VERSION ""

NS_ :

BS_:

BU_: Sensor_Board Steering_Wheel_Sensor Accelerometer Dashboard Wireless_Board Shutdown_Circuit BMS MCU Diagnostics Motor_Control VCU
VAL_TABLE_ MCU_Config_Parameter 14 "Undervoltage Min Voltage" 13 "Undervoltage Limit Gain" 12 "Undervoltage Limit" 11 "Overvoltage Limit" 10 "Motor Phase Offset Compensation" 9 "Auto-Aligning Current" 8 "Feedback Resolution" 7 "Feedback Type" 6 "Motor Temperature Sensor" 5 "Motor Rated Torque" 4 "Motor Rated Current" 3 "Motor Pole Pairs" 2 "FOC Delay" 1 "Motor type" 0 "Start up" ;
VAL_TABLE_ MCU_NMT_Mode 3 "Operational" 2 "Pre-Operational" 1 "Reset" 0 "Stopped" ;
VAL_TABLE_ Pedal_Sensor_Failure_Mode 4 "Complete pedal box failure" 3 "Brake sensor failure" 2 "Throttle sensor 2 failure" 1 "Throttle sensor 1 failure" 0 "No error, pedal sensors ok" ;
VAL_TABLE_ MCU_Error_Codes 5 "Description for the value '0x5'" 4 "Description for the value '0x4'" 3 "Description for the value '0x3'" 2 "Description for the value '0x2'" 1 "Description for the value '0x1'" 0 "Description for the value '0x0'" ;
VAL_TABLE_ Statusword_values 13 "Fault_Off" 8 "Enabled" 7 "Energised" 4 "Precharge" 2 "Shutdown" 1 "Not_ready_to_switch_on" 0 "None" ;
VAL_TABLE_ Heartbeat 127 "System in pre-operational mode" 5 "System in operational mode" 0 "boot-up" ;
VAL_TABLE_ OperationValues 128 "Return to pre-operational" 1 "Enable operational" ;
VAL_TABLE_ Fault_Codes 18575 "Sensorless Startup" 17868 "Mains Over Voltage" 19585 "HVIL loop Broken" 22401 "CANopen Anon EMCY level 5" 22337 "Invalid power Frame rating" 21711 "IGBT M3 High driver" 21710 "IGBT M3 Low driver" 21709 "IGBT M2 High driver" 21708 "IGBT M2 Low driver" 21707 "IGBT M1 High driver" 21706 "Pump FET s/c, IGBT M1 Low driver" 21705 "MOSFET short circuit checks" 21704 "MOSFET s/c M3 to B-" 21703 "MOSFET s/c M3 to B+" 21702 "MOSFET s/c M2 to B-" 21701 "MOSFET s/c M2 to B+" 21700 "MOSFET s/c M1 to B-" 21699 "MOSFET s/c M1 to B+" 21698 "Power Frame Fault" 21697 "PF Overvoltage" 21570 "Calibration Fault" 21569 "Incompatible hardware version" 21377 "CANopen EMCY level 4" 21318 "Internal Supply Out of Range" 21317 "Sheduler Stack Overflow" 21316 "DSP SPI comms Fault" 21315 "Fault List Overflow" 21314 "OSC watchdog Fault" 21313 "Invalid DSP protocol" 21274 "Ren Protocol" 21273 "Mtr Slave in wrong state" 21272 "SDO Bad Error Number" 21271 "SDO Bad SRC" 21270 "SDO Unknown" 21269 "SDO Send Error" 21268 "SDO Len Error" 21267 "SDO Rec Error" 21266 "SDO Toggle Error" 21265 "SDO State Error" 21264 "SDO Abort Error" 21263 "SDO Timeout Error" 21262 "SDO HDL Error" 21261 "CAN ESTAT set" 21260 "CANopen salve in wrong state" 21259 "CANopen Heartbeat Failed" 21258 "Short PDO Recieved" 21257 "Node guarding Failed" 21256 "CAN Off bus" 21255 "CAN overrun" 21254 "HPTX queue overrun" 21253 "HPRX queue overrun" 21252 "LPTX queue overrun" 21251 "LPRX queue overrun" 21250 "Bootup not recieved" 21249 "CANbus Fault" 21191 "Vcap Over Voltage" 21190 "di/dt Fault" 21189 "Encoder Alignment Severe" 21188 "Motor Overspeed Fault" 21187 "Current Control Fault" 21186 "Motor Over Current" 21185 "Encoder Fault" 20993 "Heatsink Overtemp" 20931 "KL 15/30 too High" 20930 "Capacitor Precharge Failure" 20929 "Power Supply Interrupt" 20872 "AOut short Circuit" 20871 "AOut Under Current" 20870 "AOut Over Temperature" 20869 "AOut Off with FS" 20868 "AOut on without FS" 20867 "Analogue Output Over Current" 20866 "Analogue Input Wire Off" 20865 "Digital Input Wire Off" 20803 "VERLOG" 20802 "Ren Signal" 20801 "BeltLoader Fault" 20738 "Line Contactro Welded" 20737 "Line Contactor O/C" 20609 "Invalid Steer Switches" 20550 "Voltage Auto Config Error" 20549 "Auto Configuration Fault" 20548 "Dynamic Range Error" 20547 "Static Range Error" 20546 "VPDO out of range" 20545 "BAD NVM data" 20353 "CANopen Anon EMCY level 3" 20311 "Motor Stalled" 20310 "Motor in Wrong Direction" 20309 "DSP Parameter Error" 20308 "AutoZero Range Error" 20307 "App Manager SS " 20306 "DSP Comms Error" 20305 "DSP Not Detected" 20304 "New Power Frame Detected" 20303 "Trac APP SS Error" 20302 "DMC SS Error" 20301 "VA SS Error" 20300 "OBD SS Error" 20299 "LCP SS Error" 20298 "LCM SS Error" 20297 "GIO SS Error" 20296 "I/O SS Error" 20295 "DSP Heartbeat Error" 20294 "Sheduler Error" 20293 "Queue Error" 20292 "Timer Failed" 20291 "General DSP Error" 20290 "Out Of Memory" 20289 "Internal Fault" 20226 "EMCY send Failed" 20225 "Unexpected Slave State" 20162 "Pulsing Disabled" 20161 "Can't Establush field current" 20097 "RPDO Timeout (severe)" 19907 "Power Supply Critical" 19779 "Motor Stalled" 19778 "Motor Open Circuit Fault" 19777 "Motor Isolation Fault" 19716 "Circuit Breaker Timeout" 19715 "DC Link Collapsed" 19714 "Circuit Breaker Welded" 19713 "Circuit Breaker Open" 19521 "Too Many Slaves" 19329 "CANopen EMCY level 2" 19203 "IO Data Error" 19202 "Ren Data" 19201 "CANbus Off (drive inhibit)" 19073 "RPDO Timeout (drive inhibit)" 18945 "Cutback" 18882 "Entering Cutback" 18819 "Direction Change" 18818 "E-Brake Wire Off" 18817 "Throttle Fault" 18754 "PST Fault" 18753 "Motor Overspeed" 18574 "Mom Dir Fault" 18573 "Belly Fault" 18572 "Tilt Sensor Fault" 18571 "Illegal Mode Fault" 18570 "Traction inhibit Fault" 18569 "Pothole Fault" 18568 "Raised and Tilted Fault" 18567 "Overload Fault" 18566 "Inch Fault" 18565 "FS1 Recycle Fault" 18564 "Sequence Fault" 18563 "SRO Fault" 18562 "Two Direction Fault" 18561 "Seat Fault" 18369 "Vehicle Service required" 18307 "24V Supply High" 18306 "24V Supplu Low" 18305 "CANopen Anon EMCY level 1" 18242 "Internal Supply Out of range" 18241 "Sheduler Stack Overflow warning" 18177 "CAN Warning" 18118 "Encoder PLL Deactivated Warning" 18117 "Stator Resistance Error" 18116 "Motor Pull-Out Warning" 18115 "Fault Ride through" 18114 "SinCos Tracking warning" 18113 "Encoder Alignment warning" 18051 "RPDO Timeout (warning)" 18050 "Io can't init" 18049 "Unit in Pre-Op" 17924 "Motor too Cold" 17923 "Motor in Thermal Cutback" 17922 "Device too hot" 17921 "Device too cold" 17870 "Vcap Vkey Diff" 17869 "KL15/30 too low" 17867 "Mains Under voltage" 17866 "Motor in high voltage cutback" 17865 "Motor in low voltage cutback" 17864 "Vcap Above rated max" 17863 "Vbat Above rated max" 17862 "Vbat Below rated min" 17861 "High Capacitor Cut" 17860 "High Battery Cut" 17859 "Low Battery Cut" 17858 "BDI Cutout" 17857 "BDI warning" 17802 "Seat warning" 17801 "Analogue Supply warning" 17800 "AOut Short Circuit (warn)" 17799 "AOut Under Current (warn)" 17798 "AOut Over Temperature (warn)" 17797 "AOut Off with Failsafe [warn]" 17796 "AOut Over Current [warn]" 17795 "Safety Case 2" 17794 "Safety Case 1" 17793 "Throttle Fault (Warn)" 17741 "Electrolyte Cutout Level" 17740 "Electrolyte Level Low" 17739 "MOSFET s/c test Waiting" 17738 "Bridge Enable Delayed" 17737 "Pulsed Enable" 17736 "Steer Sensor Warning" 17735 "Tow Mode" 17734 "No Motor Speed Signal" 17733 "Isolation Fault" 17732 "Pump Current Low" 17731 "Hydraulic Fault" 17730 "Low Oil / Device test waiting" 17729 "Fan Fault" 17537 "Handbrake Fault" ;

BO_ 3221225472 VECTOR__INDEPENDENT_SIG_MSG: 0 Vector__XXX
 SG_ Test_Sig : 0|8@1- (1,0) [0|0] "" Vector__XXX
 SG_ BrakePot_Voltage : 0|16@1+ (1,0) [0|65535] "mV" Vector__XXX
 SG_ GPS_Long : 0|16@1+ (1,0) [0|65535] "" Vector__XXX
 SG_ MCU_Error : 0|1@1+ (1,0) [0|1] "" Vector__XXX
 SG_ Motor_Temp : 0|8@1+ (1,0) [0|255] "Celsius" Vector__XXX
 SG_ MCU_Command : 0|1@1+ (1,0) [0|1] "" Vector__XXX
 SG_ GPS_Lat : 0|16@1+ (1,0) [0|65535] "" Vector__XXX
 SG_ MCU_On : 0|1@1+ (1,0) [0|1] "" Vector__XXX
 SG_ MCU_Pre_Op : 0|1@1+ (1,0) [0|1] "" Vector__XXX
 SG_ MCU_Op : 0|1@1+ (1,0) [0|1] "" Vector__XXX
 SG_ MCU_Supply_Voltage : 0|16@1+ (1,0) [0|65535] "V" Vector__XXX
 SG_ MCU_Target_Velocity : 0|32@1+ (1,0) [0|4294967295] "V" Vector__XXX
 SG_ MCU_DC_Power : 0|32@1- (1,0) [0|0] "W" Vector__XXX
 SG_ MCU_Error_Code : 0|16@1- (1,0) [0|0] "" Vector__XXX
 SG_ MCU_Status_Word : 0|16@1+ (1,0) [0|65535] "" Vector__XXX
 SG_ MCU_DC_Link_Current : 0|32@1- (1,0) [-2147483648|2147483647] "A" Vector__XXX
 SG_ MCU_DC_Link_Voltage : 0|16@1- (0.1,0) [-32768|32767] "V" Vector__XXX
 SG_ MCU_Temp : 0|8@1+ (1,0) [0|255] "Celsius" Vector__XXX
 SG_ MCU_Torque_Actual_Value : 0|16@1- (1,0) [-32768|32767] "" Vector__XXX
 SG_ MCU_Warning : 0|1@1+ (1,0) [0|1] "" Vector__XXX
 SG_ MCU_Config_Error : 0|1@1+ (1,0) [0|1] "" Vector__XXX
 SG_ Heartbeat : 0|8@1- (1,0) [0|0] "" Vector__XXX
 SG_ SDO_Specifier : 0|8@1+ (1,0) [0|0] "" Vector__XXX
 SG_ MCU_OD_Sub_Index : 0|8@1+ (1,0) [0|255] "" Vector__XXX
 SG_ MCU_OD_Index : 0|16@1+ (1,0) [0|65535] "" Vector__XXX
 SG_ SDO_Data : 0|32@1- (1,0) [0|4294967295] "" Vector__XXX
 SG_ SDO_Data : 0|32@1- (1,0) [0|4294967295] "" Vector__XXX
 SG_ MCU_OD_Sub_Index : 0|8@1+ (1,0) [0|255] "" Vector__XXX
 SG_ MCU_OD_Index : 0|16@1+ (1,0) [0|65535] "" Vector__XXX
 SG_ SDO_Specifier : 0|8@1+ (1,0) [0|255] "" Vector__XXX
 SG_ RegenSpeedSig : 0|16@1- (1,0) [0|0] "" Vector__XXX
 SG_ MCU_Torque_Request : 0|16@1- (1,0) [-1000|1000] "" Vector__XXX
 SG_ MCU_ControlWord : 0|16@1+ (1,0) [0|65535] "" Vector__XXX
 SG_ NMT_Command_0 : 0|8@1+ (1,0) [0|0] "" Vector__XXX
 SG_ Vehicle_Speed : 0|16@1+ (0.01,0) [0|655.35] "" Vector__XXX
 SG_ Rear_Wheel_Speed : 0|16@1+ (0.01,0) [0|655.35] "km/h" Vector__XXX
 SG_ Front_Left_Wheel_Interval : 0|32@1+ (1,0) [0|4294967295] "uS" Vector__XXX
 SG_ Front_Right_Wheel_Interval : 0|32@1+ (1,0) [0|4294967295] "uS" Vector__XXX
 SG_ Rear_Left_Wheel_Interval : 0|32@1+ (1,0) [0|4294967295] "uS" Vector__XXX
 SG_ Rear_Right_Wheel_Interval : 0|32@1+ (1,0) [0|4294967295] "uS" Vector__XXX

BO_ 1284 Wheel_Speed_4: 8 Vector__XXX

BO_ 1283 Wheel_Speed_3: 8 Vector__XXX

BO_ 392 MCU_TPDO5: 0 MCU

BO_ 2019 DashBMSReq: 8 Dashboard

BO_ 564 SteeringWheelSensor: 5 Steering_Wheel_Sensor
 SG_ RotationSpeed : 16|8@1+ (4,0) [0|0] "" Vector__XXX
 SG_ Acc_Angle : 0|16@1- (0.1,0) [0|0] "Degrees" Vector__XXX

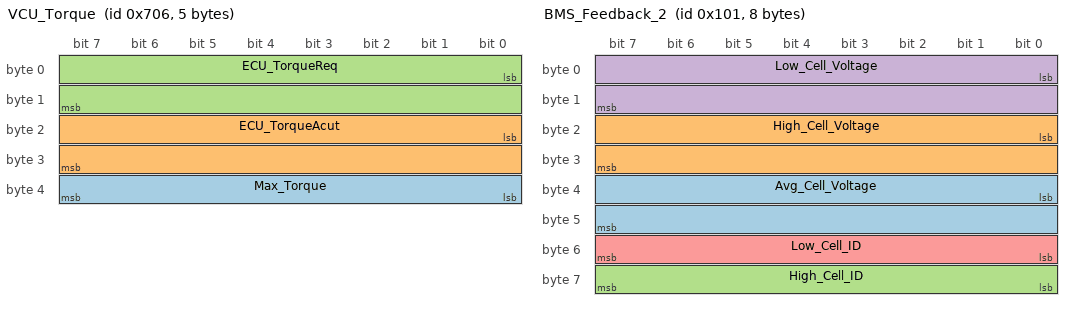
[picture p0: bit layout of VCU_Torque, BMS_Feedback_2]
BO_ 1798 VCU_Torque: 5 VCU
 SG_ Max_Torque : 32|8@1- (1,0) [0|0] "" Vector__XXX
 SG_ ECU_TorqueAcut : 16|16@1- (0.1,0) [0|0] "Percent" Vector__XXX
 SG_ ECU_TorqueReq : 0|16@1- (0.1,0) [0|0] "Percent" Vector__XXX

BO_ 380 AccelerometerZ: 8 Accelerometer
 SG_ Acc_ZAxis : 32|16@1+ (0.0001274,0) [0|0] "" Vector__XXX

BO_ 376 AccelerometerX: 8 Accelerometer
 SG_ Acc_XAxis : 32|16@1+ (0.0001274,0) [0|0] "" Vector__XXX
 SG_ Acc_Roll : 0|16@1+ (0.005,0) [0|0] "" Vector__XXX

BO_ 372 AccelerometerY: 8 Accelerometer
 SG_ Acc_YAxis : 32|16@1+ (0.0001274,0) [0|0] "" Vector__XXX
 SG_ Acc_Yaw : 0|16@1+ (0.005,0) [0|0] "" Vector__XXX

BO_ 1282 Wheel_Speeds_2: 6 Sensor_Board

BO_ 1281 Wheel_Speed_1: 6 Wireless_Board

BO_ 769 MCU_RPDO2: 8 VCU

BO_ 513 MCU_RPDO1: 0 VCU

BO_ 1077 MCU_TPDO4: 0 MCU

BO_ 338 MCU_TPDO3: 0 MCU

BO_ 569 MCU_TPDO2: 0 MCU

BO_ 272 MCU_TPDO1: 0 MCU

BO_ 257 BMS_Feedback_2: 8 BMS
 SG_ Avg_Cell_Voltage : 32|16@1+ (0.1,0) [0|6553.5] "mV" Vector__XXX
 SG_ High_Cell_Voltage : 16|16@1+ (0.1,0) [0|6553.5] "mV" Vector__XXX
 SG_ High_Cell_ID : 56|8@1+ (1,0) [0|255] "" Vector__XXX
 SG_ Low_Cell_Voltage : 0|16@1+ (0.1,0) [0|6553.5] "mV" Vector__XXX
 SG_ Low_Cell_ID : 48|8@1+ (1,0) [0|255] "" Vector__XXX

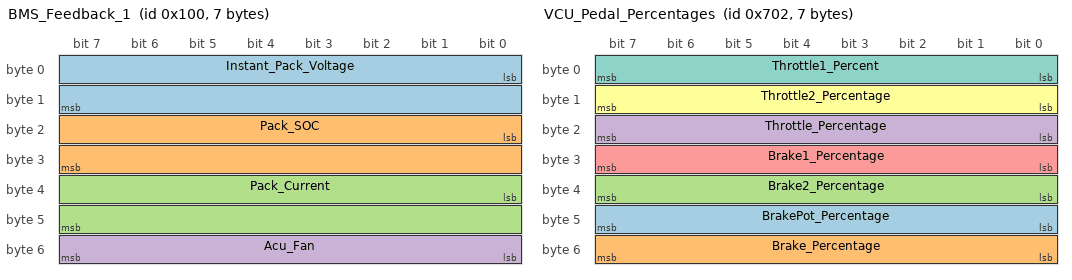
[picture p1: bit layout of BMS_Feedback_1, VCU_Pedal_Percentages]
BO_ 256 BMS_Feedback_1: 7 BMS
 SG_ Instant_Pack_Voltage : 0|16@1+ (1,0) [0|65535] "" Vector__XXX
 SG_ Pack_SOC : 16|16@1+ (1,0) [0|65535] "" Vector__XXX
 SG_ Pack_Current : 32|16@1- (1,64) [0|65535] "" Vector__XXX
 SG_ Acu_Fan : 48|8@1+ (1,0) [0|255] "" Vector__XXX

BO_ 1792 VCU_Diagnostics: 8 VCU
 SG_ VCU_Year : 48|8@1+ (1,0) [0|255] "" Vector__XXX
 SG_ VCU_Version : 56|8@1+ (1,0) [0|255] "" Vector__XXX
 SG_ VCU_Month : 40|8@1+ (1,0) [0|255] "" Vector__XXX
 SG_ VCU_Day : 35|5@1+ (1,0) [0|31] "" Vector__XXX
 SG_ Boost_on : 34|1@1- (1,0) [0|0] "" Vector__XXX
 SG_ TC_on : 33|1@1- (1,0) [0|0] "" Vector__XXX
 SG_ RegenBool : 32|1@1- (1,0) [0|0] "" Vector__XXX
 SG_ Fault_ECU_Shutdown : 22|1@1- (1,0) [0|0] "" Vector__XXX
 SG_ Low_AIR_Status : 20|1@1- (1,0) [0|0] "" Vector__XXX
 SG_ High_AIR_Status : 21|1@1+ (1,0) [0|1] "" Vector__XXX
 SG_ BPPS_Implausibility : 16|1@1- (1,0) [0|0] "" Vector__XXX
 SG_ Pedal_Sensor_Fail : 24|8@1+ (1,0) [0|7] "" Vector__XXX
 SG_ APPS_Implausibility : 17|1@1+ (1,0) [0|1] "" Vector__XXX
 SG_ APPS_BP_Implausibility : 18|1@1+ (1,0) [0|1] "" Vector__XXX
 SG_ GearingRatio : 8|8@1+ (0.1,0) [0|0] "" Vector__XXX
 SG_ Wheel_Size : 0|8@1+ (0.1,0) [0|25.5] "m" Vector__XXX
 SG_ Fault_CarShutdown : 23|1@1+ (1,0) [0|1] "" Vector__XXX
 SG_ LV_Battery_Warning : 19|1@1+ (1,0) [0|1] "" Vector__XXX

BO_ 1794 VCU_Pedal_Percentages: 7 VCU
 SG_ BrakePot_Percentage : 40|8@1+ (1,0) [0|255] "%" Vector__XXX
 SG_ Brake_Percentage : 48|8@1+ (1,0) [0|255] "%" Vector__XXX
 SG_ Brake2_Percentage : 32|8@1+ (1,0) [0|255] "%" Vector__XXX
 SG_ Throttle_Percentage : 16|8@1+ (1,0) [0|255] "%" Vector__XXX
 SG_ Brake1_Percentage : 24|8@1+ (1,0) [0|255] "%" Vector__XXX
 SG_ Throttle2_Percentage : 8|8@1+ (1,0) [0|255] "%" Vector__XXX
 SG_ Throttle1_Percent : 0|8@1+ (1,0) [0|255] "%" Vector__XXX

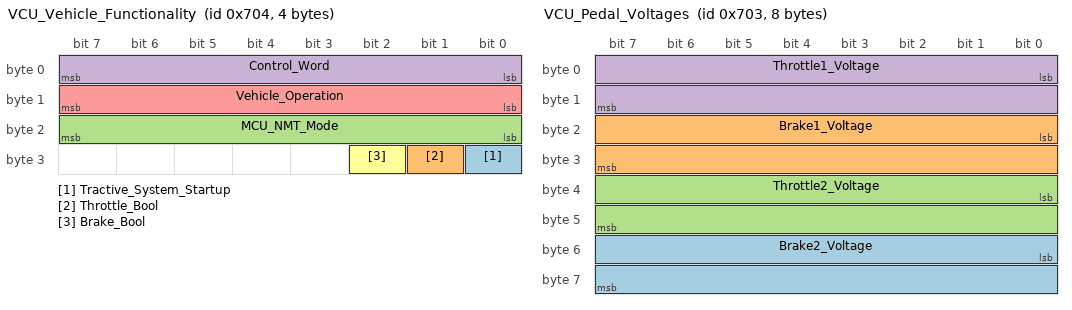
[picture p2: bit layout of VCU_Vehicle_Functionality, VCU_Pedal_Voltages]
BO_ 1796 VCU_Vehicle_Functionality: 4 VCU
 SG_ Tractive_System_Startup : 24|1@1+ (1,0) [0|255] "" Vector__XXX
 SG_ Throttle_Bool : 25|1@1+ (1,0) [0|1] "" Vector__XXX
 SG_ MCU_NMT_Mode : 16|8@1+ (1,0) [0|255] "" Vector__XXX
 SG_ Control_Word : 0|8@1+ (1,0) [0|1] "" Vector__XXX
 SG_ Vehicle_Operation : 8|8@1+ (1,0) [0|15] "" Vector__XXX
 SG_ Brake_Bool : 26|1@1+ (1,0) [0|1] "" Vector__XXX

BO_ 1795 VCU_Pedal_Voltages: 8 VCU
 SG_ Brake2_Voltage : 48|16@1+ (1,0) [0|65535] "mV" Vector__XXX
 SG_ Brake1_Voltage : 16|16@1+ (1,0) [0|65535] "mV" Vector__XXX
 SG_ Throttle2_Voltage : 32|16@1+ (1,0) [0|65535] "mV" Vector__XXX
 SG_ Throttle1_Voltage : 0|16@1+ (1,0) [0|65535] "mV" Vector__XXX

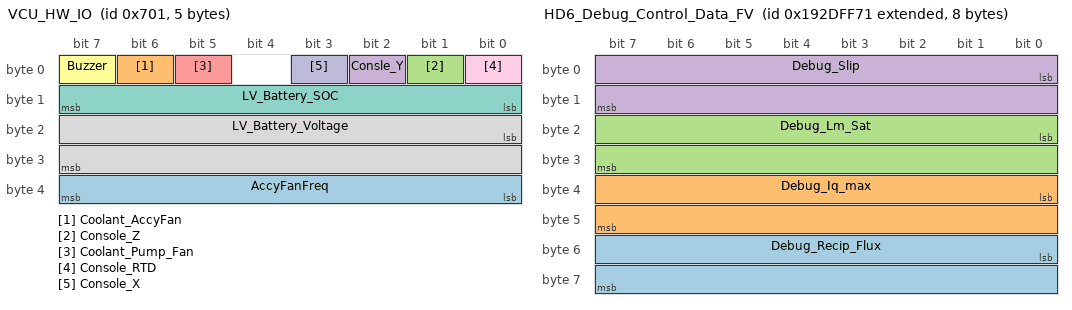
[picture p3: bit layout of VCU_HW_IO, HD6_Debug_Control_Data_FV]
BO_ 1793 VCU_HW_IO: 5 VCU
 SG_ AccyFanFreq : 32|8@1+ (1,0) [0|0] "Hz" Vector__XXX
 SG_ Coolant_AccyFan : 6|1@1- (1,0) [0|0] "" Vector__XXX
 SG_ Console_Z : 1|1@1- (1,0) [0|0] "" Vector__XXX
 SG_ Consle_Y : 2|1@1- (1,0) [0|0] "Bool" Vector__XXX
 SG_ Coolant_Pump_Fan : 5|1@1+ (1,0) [0|1] "" Vector__XXX
 SG_ Buzzer : 7|1@1+ (1,0) [0|1] "" Vector__XXX
 SG_ LV_Battery_SOC : 8|8@1+ (1,0) [0|255] "" Vector__XXX
 SG_ LV_Battery_Voltage : 16|16@1+ (1,0) [0|65535] "mV" Vector__XXX
 SG_ Console_RTD : 0|1@1+ (1,0) [0|1] "Bool" Vector__XXX
 SG_ Console_X : 3|1@1+ (1,0) [0|1] "Bool" Vector__XXX

BO_ 112 MCU_NMT_Broadcast: 1 VCU
 SG_ NMT_Command : 0|8@1+ (1,0) [0|255] "" Vector__XXX

BO_ 128 MCU_Sync_MSG: 0 VCU

BO_ 2568814449 HS5_Encoder_Info: 8 Motor_Control
 SG_ Encoder_pos : 0|32@1- (1.52587890625E-005,0) [0|0] "rotations" Vector__XXX

BO_ 2569928561 HD6_Debug_Control_Data_FV: 8 Motor_Control
 SG_ Debug_Recip_Flux : 48|16@1- (1,0) [0|0] "1/A" Vector__XXX
 SG_ Debug_Iq_max : 32|16@1- (1,0) [0|0] "A" Vector__XXX
 SG_ Debug_Lm_Sat : 16|16@1- (1.52587890625E-005,0) [0|0] "H" Vector__XXX
 SG_ Debug_Slip : 0|16@1- (0.0625,0) [0|0] "rad/s" Vector__XXX

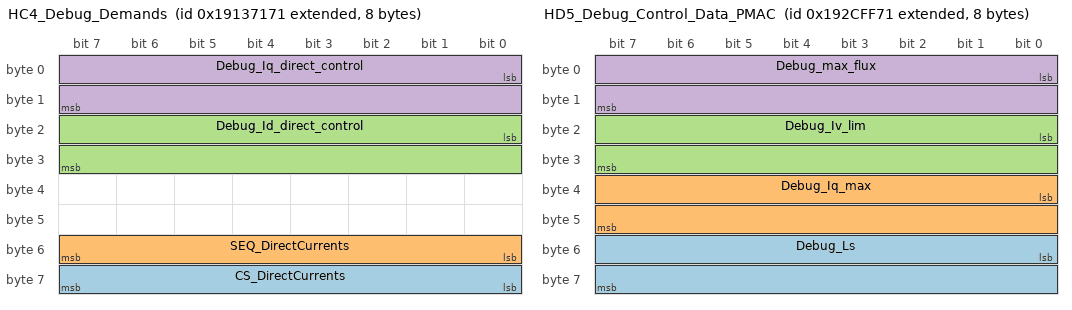
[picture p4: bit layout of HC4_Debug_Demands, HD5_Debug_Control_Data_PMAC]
BO_ 2568188273 HC4_Debug_Demands: 8 Motor_Control
 SG_ CS_DirectCurrents : 56|8@1+ (1,0) [0|0] "" Vector__XXX
 SG_ SEQ_DirectCurrents : 48|8@1+ (1,0) [0|0] "" Vector__XXX
 SG_ Debug_Id_direct_control : 16|16@1- (0.0625,0) [0|0] "A" Vector__XXX
 SG_ Debug_Iq_direct_control : 0|16@1- (0.0625,0) [0|0] "A" Vector__XXX

BO_ 2569863025 HD5_Debug_Control_Data_PMAC: 8 Motor_Control
 SG_ Debug_Ls : 48|16@1- (5.960464477539E-008,0) [0|0] "H" Vector__XXX
 SG_ Debug_Iq_max : 32|16@1- (1,0) [0|0] "A" Vector__XXX
 SG_ Debug_Iv_lim : 16|16@1- (1,0) [0|0] "A" Vector__XXX
 SG_ Debug_max_flux : 0|16@1- (1,0) [0|0] "A" Vector__XXX

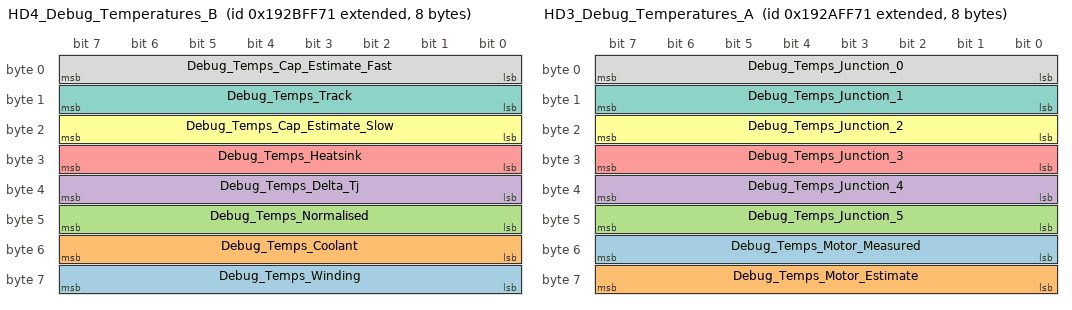
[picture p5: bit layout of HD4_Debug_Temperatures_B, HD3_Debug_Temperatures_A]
BO_ 2569797489 HD4_Debug_Temperatures_B: 8 Motor_Control
 SG_ Debug_Temps_Winding : 56|8@1+ (1,0) [0|0] "degC" Vector__XXX
 SG_ Debug_Temps_Coolant : 48|8@1+ (1,0) [0|0] "degC" Vector__XXX
 SG_ Debug_Temps_Normalised : 40|8@1+ (1,0) [0|255] "degC" Vector__XXX
 SG_ Debug_Temps_Delta_Tj : 32|8@1+ (1,0) [0|255] "degC" Vector__XXX
 SG_ Debug_Temps_Heatsink : 24|8@1+ (1,0) [0|255] "degC" Vector__XXX
 SG_ Debug_Temps_Cap_Estimate_Slow : 16|8@1+ (1,0) [0|255] "degC" Vector__XXX
 SG_ Debug_Temps_Track : 8|8@1+ (1,0) [0|255] "degC" Vector__XXX
 SG_ Debug_Temps_Cap_Estimate_Fast : 0|8@1+ (1,0) [0|255] "degC" Vector__XXX

BO_ 2569731953 HD3_Debug_Temperatures_A: 8 Motor_Control
 SG_ Debug_Temps_Motor_Measured : 48|8@1+ (1,0) [0|255] "degC" Vector__XXX
 SG_ Debug_Temps_Motor_Estimate : 56|8@1+ (1,0) [0|255] "degC" Vector__XXX
 SG_ Debug_Temps_Junction_5 : 40|8@1+ (1,0) [0|255] "degC" Vector__XXX
 SG_ Debug_Temps_Junction_4 : 32|8@1+ (1,0) [0|255] "degC" Vector__XXX
 SG_ Debug_Temps_Junction_3 : 24|8@1+ (1,0) [0|255] "degC" Vector__XXX
 SG_ Debug_Temps_Junction_2 : 16|8@1+ (1,0) [0|255] "degC" Vector__XXX
 SG_ Debug_Temps_Junction_1 : 8|8@1+ (1,0) [0|255] "degC" Vector__XXX
 SG_ Debug_Temps_Junction_0 : 0|8@1+ (1,0) [0|255] "degC" Vector__XXX

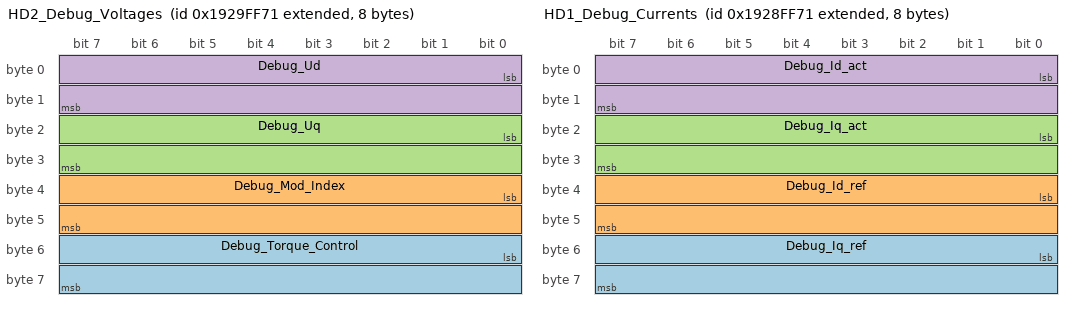
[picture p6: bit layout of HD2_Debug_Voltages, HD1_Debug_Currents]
BO_ 2569666417 HD2_Debug_Voltages: 8 Motor_Control
 SG_ Debug_Torque_Control : 48|16@1- (0.0625,0) [0|0] "Nm" Vector__XXX
 SG_ Debug_Mod_Index : 32|16@1+ (0.00390625,0) [0|0] "%" Vector__XXX
 SG_ Debug_Uq : 16|16@1- (0.0625,0) [0|0] "V" Vector__XXX
 SG_ Debug_Ud : 0|16@1- (0.0625,0) [0|0] "V" Vector__XXX

BO_ 2569600881 HD1_Debug_Currents: 8 Motor_Control
 SG_ Debug_Iq_ref : 48|16@1- (0.0625,0) [0|0] "A" Vector__XXX
 SG_ Debug_Id_ref : 32|16@1- (0.0625,0) [0|0] "A" Vector__XXX
 SG_ Debug_Iq_act : 16|16@1- (0.0625,0) [0|0] "A" Vector__XXX
 SG_ Debug_Id_act : 0|16@1- (0.0625,0) [0|0] "A" Vector__XXX

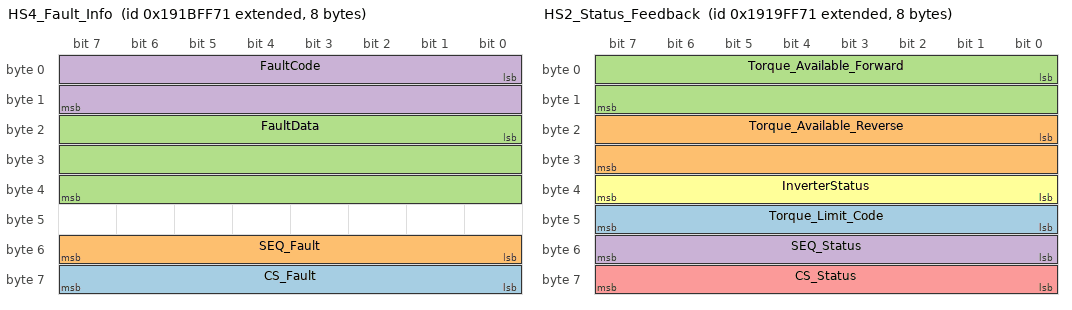
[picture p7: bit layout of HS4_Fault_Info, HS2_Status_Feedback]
BO_ 2568748913 HS4_Fault_Info: 8 Motor_Control
 SG_ CS_Fault : 56|8@1+ (1,0) [0|255] ""  VCU
 SG_ SEQ_Fault : 48|8@1+ (1,0) [0|255] ""  VCU
 SG_ FaultData : 16|24@1- (1,0) [0|0] ""  VCU
 SG_ FaultCode : 0|16@1- (1,0) [0|0] ""  VCU

BO_ 2568617841 HS2_Status_Feedback: 8 Motor_Control
 SG_ Torque_Limit_Code : 40|8@1+ (1,0) [0|0] "" Vector__XXX
 SG_ Torque_Available_Reverse : 16|16@1- (0.0625,0) [0|0] "Nm"  VCU
 SG_ Torque_Available_Forward : 0|16@1- (0.0625,0) [0|0] "Nm"  VCU
 SG_ SEQ_Status : 48|8@1+ (1,0) [0|255] ""  VCU
 SG_ CS_Status : 56|8@1+ (1,0) [0|255] ""  VCU
 SG_ InverterStatus : 32|8@1+ (1,0) [0|255] "-"  VCU

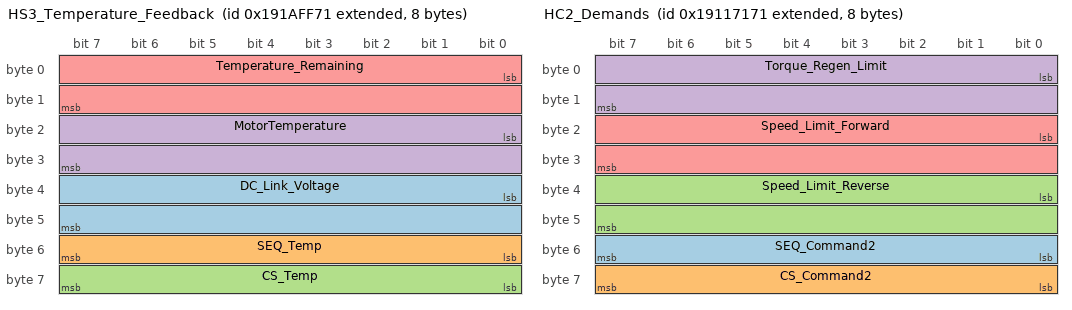
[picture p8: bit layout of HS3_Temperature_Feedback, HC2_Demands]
BO_ 2568683377 HS3_Temperature_Feedback: 8 Motor_Control
 SG_ DC_Link_Voltage : 32|16@1- (0.0625,0) [-2048|2047.9375] "V"  VCU
 SG_ SEQ_Temp : 48|8@1+ (1,0) [0|255] ""  VCU
 SG_ CS_Temp : 56|8@1+ (1,0) [0|255] ""  VCU
 SG_ MotorTemperature : 16|16@1- (1,0) [-32768|32767] "C"  VCU
 SG_ Temperature_Remaining : 0|16@1- (1,0) [-32768|32767] "C"  VCU

BO_ 2568057201 HC2_Demands: 8 VCU
 SG_ SEQ_Command2 : 48|8@1+ (1,0) [0|255] ""  Motor_Control
 SG_ CS_Command2 : 56|8@1+ (1,0) [0|255] ""  Motor_Control
 SG_ Speed_Limit_Reverse : 32|16@1- (1,0) [-32768|32767] "RPM"  Motor_Control
 SG_ Torque_Regen_Limit : 0|16@1- (0.0625,0) [0|0] "Nm"  Motor_Control
 SG_ Speed_Limit_Forward : 16|16@1- (1,0) [-32768|32767] "RPM"  Motor_Control

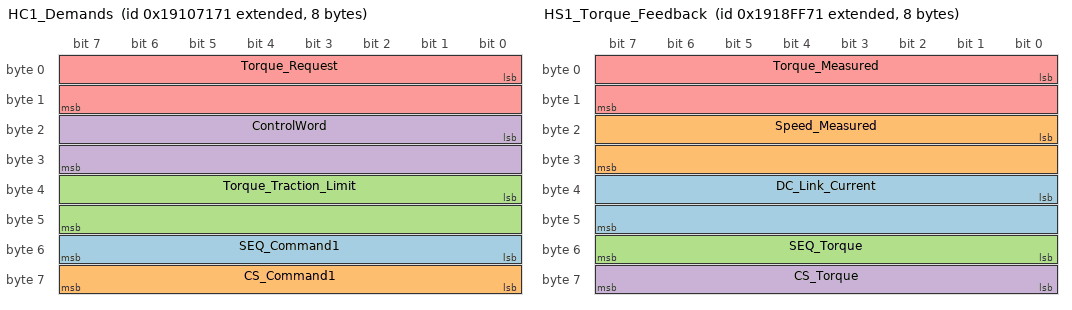
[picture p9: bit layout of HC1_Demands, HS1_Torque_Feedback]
BO_ 2567991665 HC1_Demands: 8 VCU
 SG_ SEQ_Command1 : 48|8@1+ (1,0) [0|255] ""  Motor_Control
 SG_ CS_Command1 : 56|8@1+ (1,0) [0|255] ""  Motor_Control
 SG_ Torque_Traction_Limit : 32|16@1- (0.0625,0) [0|0] "Nm"  Motor_Control
 SG_ ControlWord : 16|16@1- (1,0) [0|0] ""  Motor_Control
 SG_ Torque_Request : 0|16@1- (0.0625,0) [0|0] "Nm"  Motor_Control

BO_ 2568552305 HS1_Torque_Feedback: 8 Motor_Control
 SG_ DC_Link_Current : 32|16@1- (1,0) [-32768|32767] "A"  VCU
 SG_ Speed_Measured : 16|16@1- (1,0) [-32768|32767] "RPM"  VCU
 SG_ SEQ_Torque : 48|8@1+ (1,0) [0|255] ""  VCU
 SG_ CS_Torque : 56|8@1+ (1,0) [0|255] ""  VCU
 SG_ Torque_Measured : 0|16@1- (0.0625,0) [0|0] "Nm"  VCU

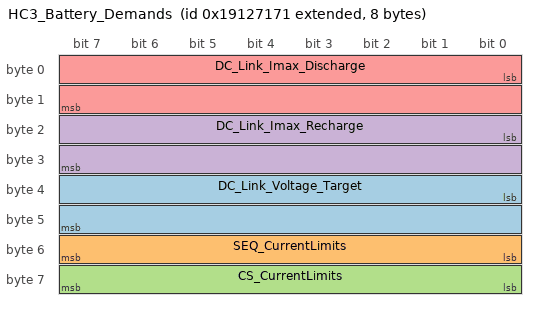
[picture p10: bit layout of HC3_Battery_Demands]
BO_ 2568122737 HC3_Battery_Demands: 8 VCU
 SG_ DC_Link_Voltage_Target : 32|16@1- (0.0625,0) [0|0] "V" Vector__XXX
 SG_ SEQ_CurrentLimits : 48|8@1+ (1,0) [0|255] ""  Motor_Control
 SG_ CS_CurrentLimits : 56|8@1+ (1,0) [0|255] ""  Motor_Control
 SG_ DC_Link_Imax_Recharge : 16|16@1- (1,0) [-1000|0] "A"  Motor_Control
 SG_ DC_Link_Imax_Discharge : 0|16@1- (1,0) [0|1000] "A"  Motor_Control

BO_ 1797 Shutdown_Data: 3 Shutdown_Circuit
 SG_ Fault_Latched_Shutdown : 1|1@1- (1,0) [0|0] "" Vector__XXX
 SG_ Fault_PCB_Shutdown : 4|1@1- (1,0) [0|0] "" Vector__XXX
 SG_ Fault_LatchIMD_Shutdown : 19|1@1- (1,0) [0|0] "" Vector__XXX
 SG_ Fault_LatchBSPD_Shutdown : 20|1@1+ (1,0) [0|1] "" Vector__XXX
 SG_ Fault_LatchBMS_Shutdown : 18|1@1- (1,0) [0|0] "" Vector__XXX
 SG_ Fault_Interlock_Shutdown : 11|1@1- (1,0) [0|0] "" Vector__XXX
 SG_ Fault_Inertia_Shutdown : 7|1@1- (1,0) [0|0] "" Vector__XXX
 SG_ Fault_Fuse_Shutdown : 3|1@1- (1,0) [0|0] "" Vector__XXX
 SG_ Fault_ECU_Shutdown : 12|1@1- (1,0) [0|0] "" Vector__XXX
 SG_ Fault_Current : 16|1@1- (1,0) [0|0] "" Vector__XXX
 SG_ Fault_CarShutdown : 0|1@1+ (1,0) [0|1] "" Vector__XXX
 SG_ Fault_BSPD : 17|1@1+ (1,0) [0|1] "" Vector__XXX
 SG_ Fault_Brake : 15|1@1- (1,0) [0|0] "" Vector__XXX
 SG_ Fault_Any : 2|1@1+ (1,0) [0|1] "" Vector__XXX
 SG_ Fault_TSMS_Shutdown : 9|1@1+ (1,0) [0|1] "" Vector__XXX
 SG_ Fault_HVD_Shutdown : 10|1@1+ (1,0) [0|1] "" Vector__XXX
 SG_ Fault_BOTS_Shutdown : 5|1@1+ (1,0) [0|1] "" Vector__XXX
 SG_ Fault_IMD : 14|1@1+ (1,0) [0|1] "" Vector__XXX
 SG_ Fault_BMS : 13|1@1+ (1,0) [0|1] "" Vector__XXX
 SG_ Fault_ESTP_RollHoop_Shutdown : 8|1@1+ (1,0) [0|1] "" Vector__XXX
 SG_ Fault_ESTP_Dash_Shutdown : 6|1@1+ (1,0) [0|1] "" Vector__XXX

CM_ BU_ Motor_Control "Torque generating inverter";
CM_ BU_ VCU "Central vehicle control unit, responsible for generating torque demands for the inverter";
CM_ BO_ 3221225472 "This is a message for not used signals, created by Vector CANdb++ DBC OLE DB Provider.";
CM_ SG_ 1792 Low_AIR_Status "1 - Closed
0 - Open";
CM_ SG_ 1792 High_AIR_Status "1 - Closed
0 - Open";
CM_ SG_ 2569666417 Debug_Torque_Control "Torque that is to be used as the control value for caluclating current references";
CM_ SG_ 2568748913 CS_Fault "Command1 message checksum";
CM_ SG_ 2568748913 SEQ_Fault "Command1 message sequence counter";
CM_ BO_ 2568617841 "To command the anciliary switch";
CM_ SG_ 2568617841 Torque_Available_Reverse "Torque available calculated by inverter";
CM_ SG_ 2568617841 Torque_Available_Forward "Torque available calculated by inverter";
CM_ SG_ 2568617841 SEQ_Status "Status message sequence counter";
CM_ SG_ 2568617841 CS_Status "Status message checksum";
CM_ SG_ 2568617841 InverterStatus "Inverter status (TBD)";
CM_ BO_ 2568683377 "To command the anciliary switch";
CM_ SG_ 2568683377 SEQ_Temp "Temperature message sequence counter";
CM_ SG_ 2568683377 CS_Temp "Temperature message checksum";
CM_ SG_ 2568683377 MotorTemperature "Measured motor temperature";
CM_ SG_ 2568683377 Temperature_Remaining "Inverter module temperature";
CM_ BO_ 2568057201 "Active derates and values";
CM_ SG_ 2568057201 SEQ_Command2 "Command2 message sequence counter";
CM_ SG_ 2568057201 CS_Command2 "Command2 message checksum";
CM_ SG_ 2568057201 Speed_Limit_Reverse "Maximum reverse speed of motor";
CM_ SG_ 2568057201 Torque_Regen_Limit "Torque limit specified by VCM";
CM_ SG_ 2568057201 Speed_Limit_Forward "Maximum forward speed of motor";
CM_ BO_ 2567991665 "Active derates and values";
CM_ SG_ 2567991665 SEQ_Command1 "Command1 message sequence counter";
CM_ SG_ 2567991665 CS_Command1 "Command1 message checksum";
CM_ SG_ 2567991665 Torque_Traction_Limit "Max torque calculated by VCM";
CM_ SG_ 2567991665 ControlWord "Control word that sets inverter mode of operation";
CM_ SG_ 2567991665 Torque_Request "Motor torque requested by VCM";
CM_ BO_ 2568552305 "To command the anciliary switch";
CM_ SG_ 2568552305 DC_Link_Current "Net current flow measured by the inverter";
CM_ SG_ 2568552305 Speed_Measured "Measured motor speed by inverter";
CM_ SG_ 2568552305 SEQ_Torque "Torque message sequence counter";
CM_ SG_ 2568552305 CS_Torque "Torque message checksum";
CM_ SG_ 2568552305 Torque_Measured "Torque calculated by DSP in inverter";
CM_ BO_ 2568122737 "Response back to BMS";
CM_ SG_ 2568122737 DC_Link_Voltage_Target "Min motor current calculated by VCM (regen)";
CM_ SG_ 2568122737 SEQ_CurrentLimits "Current limits message sequence counter";
CM_ SG_ 2568122737 CS_CurrentLimits "Current limits message checksum";
CM_ SG_ 2568122737 DC_Link_Imax_Recharge "Min motor current calculated by VCM (regen)";
CM_ SG_ 2568122737 DC_Link_Imax_Discharge "Max motor current calculated by VCM (traction)";
BA_DEF_ SG_  "GenSigSendType" ENUM  "Cyclic","OnWrite","OnWriteWithRepetition","OnChange","OnChangeWithRepetition","IfActive","IfActiveWithRepetition","NoSigSendType";
BA_DEF_ BO_  "GenMsgSendType" ENUM  "Cyclic","not_used","not_used","not_used","not_used","Cyclic","not_used","IfActive","NoMsgSendType";
BA_DEF_ BU_  "NmStationAddress" HEX 0 0;
BA_DEF_  "DBName" STRING ;
BA_DEF_  "BusType" STRING ;
BA_DEF_DEF_  "GenSigSendType" "Cyclic";
BA_DEF_DEF_  "GenMsgSendType" "NoMsgSendType";
BA_DEF_DEF_  "NmStationAddress" 0;
BA_DEF_DEF_  "DBName" "";
BA_DEF_DEF_  "BusType" "CAN";
BA_ "DBName" "TBRe19";
BA_ "NmStationAddress" BU_ Sensor_Board 7;
BA_ "NmStationAddress" BU_ Steering_Wheel_Sensor 9;
BA_ "NmStationAddress" BU_ Accelerometer 8;
BA_ "NmStationAddress" BU_ Dashboard 4;
BA_ "NmStationAddress" BU_ Wireless_Board 6;
BA_ "NmStationAddress" BU_ Shutdown_Circuit 5;
BA_ "NmStationAddress" BU_ BMS 3;
BA_ "NmStationAddress" BU_ MCU 1;
BA_ "NmStationAddress" BU_ Diagnostics 11;
BA_ "NmStationAddress" BU_ Motor_Control 10;
BA_ "NmStationAddress" BU_ VCU 2;
VAL_ 1792 Pedal_Sensor_Fail 5 "Complete pedal box failure" 4 "Brake sensor failure" 3 "Both throttles failed" 2 "Throttle sensor 2 failure" 1 "Throttle sensor 1 failure" 0 "No error, pedal sensors ok" ;
VAL_ 1796 MCU_NMT_Mode 3 "Operational" 2 "Pre-Operational" 1 "Reset" 0 "Stopped" ;
